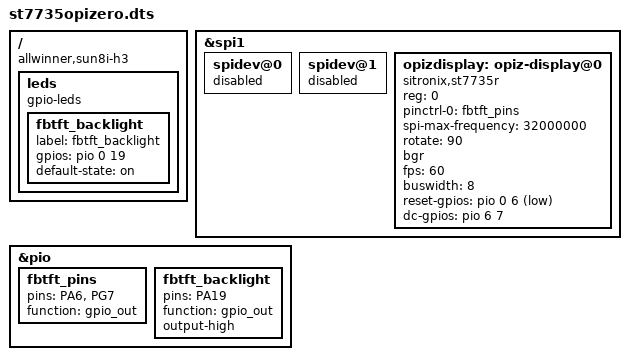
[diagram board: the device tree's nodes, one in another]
// https://github.com/nuharaf/fbtft-dt-overlay

/dts-v1/;
/plugin/;

/ {
	compatible = "allwinner,sun8i-h3";

	fragment@0 {
		target = <&spi1>;
		__overlay__ {
			status = "okay";

			spidev@0{
				status = "disabled";
			};

			spidev@1{
				status = "disabled";
			};
		};
	};

	fragment@1 {
		target = <&pio>;
		__overlay__ {
			fbtft_pins: fbtft_pins {
                pins = "PA6", "PG7";
                function = "gpio_out";
			};
			fbtft_backlight: fbtft_backlight {
				pins = "PA19";
				function = "gpio_out";
				output-high;
			};
		};
	};

	fragment@2 {
		target-path = "/";
		__overlay__ {
            leds {
                compatible = "gpio-leds";

                fbtft_backlight {
                    label = "fbtft_backlight";
                    gpios =  <&pio 0 19 0>; // port A=0 pin0=0 output=0
                    default-state = "on";
                };
            };
		};
	};
	fragment@4 {
		target = <&spi1>;
		__overlay__ {
			/* needed to avoid dtc warning */
			#address-cells = <1>;
			#size-cells = <0>;

			opizdisplay: opiz-display@0{
				compatible = "sitronix,st7735r";
				reg = <0>;
				pinctrl-names = "default";
				pinctrl-0 = <&fbtft_pins>;

				spi-max-frequency = <32000000>;
				rotate = <90>;
				bgr;
				fps = <60>;
				buswidth = <8>;
				reset-gpios = <&pio 0 6 1>;
				dc-gpios = <&pio 6 7 0>;
			};
		};
	};
};
